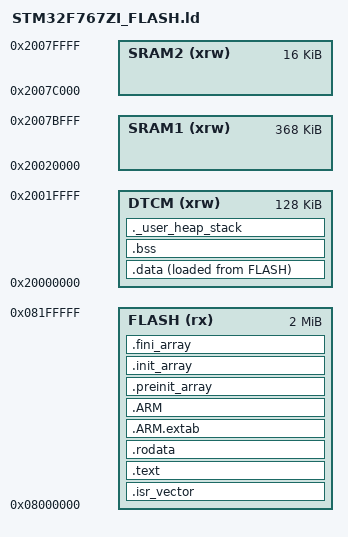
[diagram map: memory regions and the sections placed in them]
/* Minimal linker script — STM32F767ZI (2 MB flash, 512 KB RAM).
 *
 * All data/bss lives in DTCM (128 KB @ 0x20000000): it is never cached, so
 * the ViewAlyzer RAM-buffer ring stays debugger-coherent even if someone
 * enables the D-cache later, and it sits inside the ViewAlyzer app's default
 * control-block scan window (0x20000000 + 128 KB). SRAM1/2 are unused.
 */
ENTRY(Reset_Handler)

_estack = ORIGIN(DTCM) + LENGTH(DTCM);    /* stack at top of DTCM */

_Min_Heap_Size  = 0x200;
_Min_Stack_Size = 0x800;

MEMORY
{
  FLASH (rx)  : ORIGIN = 0x08000000, LENGTH = 2048K
  DTCM  (xrw) : ORIGIN = 0x20000000, LENGTH = 128K
  SRAM1 (xrw) : ORIGIN = 0x20020000, LENGTH = 368K
  SRAM2 (xrw) : ORIGIN = 0x2007C000, LENGTH = 16K
}

SECTIONS
{
  .isr_vector :
  {
    . = ALIGN(4);
    KEEP(*(.isr_vector))
    . = ALIGN(4);
  } >FLASH

  .text :
  {
    . = ALIGN(4);
    *(.text)
    *(.text*)
    *(.glue_7)
    *(.glue_7t)
    *(.eh_frame)
    KEEP (*(.init))
    KEEP (*(.fini))
    . = ALIGN(4);
    _etext = .;
  } >FLASH

  .rodata :
  {
    . = ALIGN(4);
    *(.rodata)
    *(.rodata*)
    . = ALIGN(4);
  } >FLASH

  .ARM.extab (READONLY) : { *(.ARM.extab* .gnu.linkonce.armextab.*) } >FLASH
  .ARM (READONLY)       : { __exidx_start = .; *(.ARM.exidx*) __exidx_end = .; } >FLASH

  .preinit_array (READONLY) :
  {
    PROVIDE_HIDDEN (__preinit_array_start = .);
    KEEP (*(.preinit_array*))
    PROVIDE_HIDDEN (__preinit_array_end = .);
  } >FLASH
  .init_array (READONLY) :
  {
    PROVIDE_HIDDEN (__init_array_start = .);
    KEEP (*(SORT(.init_array.*)))
    KEEP (*(.init_array*))
    PROVIDE_HIDDEN (__init_array_end = .);
  } >FLASH
  .fini_array (READONLY) :
  {
    PROVIDE_HIDDEN (__fini_array_start = .);
    KEEP (*(SORT(.fini_array.*)))
    KEEP (*(.fini_array*))
    PROVIDE_HIDDEN (__fini_array_end = .);
  } >FLASH

  _sidata = LOADADDR(.data);

  .data :
  {
    . = ALIGN(4);
    _sdata = .;
    *(.data)
    *(.data*)
    . = ALIGN(4);
    _edata = .;
  } >DTCM AT> FLASH

  . = ALIGN(4);
  .bss :
  {
    _sbss = .;
    __bss_start__ = _sbss;
    *(.bss)
    *(.bss*)
    *(COMMON)
    . = ALIGN(4);
    _ebss = .;
    __bss_end__ = _ebss;
  } >DTCM

  ._user_heap_stack :
  {
    . = ALIGN(8);
    PROVIDE ( end = . );
    PROVIDE ( _end = . );
    . = . + _Min_Heap_Size;
    . = . + _Min_Stack_Size;
    . = ALIGN(8);
  } >DTCM

  /DISCARD/ :
  {
    libc.a ( * )
    libm.a ( * )
    libgcc.a ( * )
  }

  .ARM.attributes 0 : { *(.ARM.attributes) }
}
